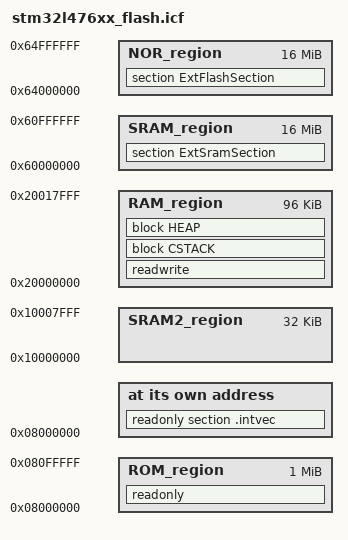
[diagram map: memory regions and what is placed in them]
/*###ICF### Section handled by ICF editor, don't touch! ****/
/*-Editor annotation file-*/
/* IcfEditorFile="$TOOLKIT_DIR$\config\ide\IcfEditor\cortex_v1_0.xml" */
/*-Specials-*/
define symbol __ICFEDIT_intvec_start__ = 0x08000000;
/*-Memory Regions-*/
define symbol __ICFEDIT_region_ROM_start__   = 0x08000000;
define symbol __ICFEDIT_region_ROM_end__     = 0x080FFFFF;
define symbol __ICFEDIT_region_RAM_start__   = 0x20000000;
define symbol __ICFEDIT_region_RAM_end__     = 0x20017FFF;
define symbol __ICFEDIT_region_SRAM2_start__ = 0x10000000;
define symbol __ICFEDIT_region_SRAM2_end__   = 0x10007FFF;

/*-Sizes-*/
define symbol __ICFEDIT_size_cstack__ = 0x800;
define symbol __ICFEDIT_size_heap__   = 0xF00;
/**** End of ICF editor section. ###ICF###*/

define symbol __region_NOR_start__ = 0x64000000;
define symbol __region_NOR_end__   = 0x64FFFFFF;
define symbol __region_SRAM_start__ = 0x60000000;
define symbol __region_SRAM_end__   = 0x60FFFFFF;

define memory mem with size = 4G;
define region ROM_region      = mem:[from __ICFEDIT_region_ROM_start__   to __ICFEDIT_region_ROM_end__];
define region RAM_region      = mem:[from __ICFEDIT_region_RAM_start__   to __ICFEDIT_region_RAM_end__];
define region SRAM2_region    = mem:[from __ICFEDIT_region_SRAM2_start__   to __ICFEDIT_region_SRAM2_end__];
define region NOR_region   = mem:[from __region_NOR_start__ to __region_NOR_end__];
define region SRAM_region   = mem:[from __region_SRAM_start__ to __region_SRAM_end__];

define block CSTACK    with alignment = 8, size = __ICFEDIT_size_cstack__   { };
define block HEAP      with alignment = 8, size = __ICFEDIT_size_heap__     { };

initialize by copy { readwrite };
do not initialize  { section .noinit };

place at address mem:__ICFEDIT_intvec_start__ { readonly section .intvec };

place in ROM_region   { readonly };
place in RAM_region   { readwrite,
                        block CSTACK, block HEAP };
place in NOR_region { section ExtFlashSection };                        
place in SRAM_region { section ExtSramSection };                        
place in SRAM2_region { };
                        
